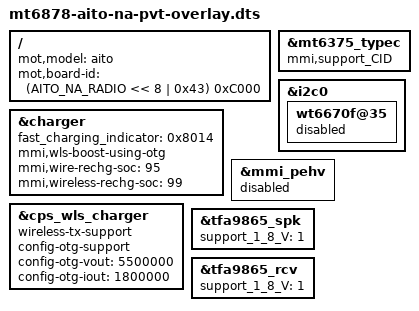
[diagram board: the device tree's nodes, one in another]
/* Copyright (c) 2023, Motorola Mobility Inc. All rights reserved.
 *
 * This program is free software; you can redistribute it and/or modify
 * it under the terms of the GNU General Public License version 2 and
 * only version 2 as published by the Free Software Foundation.
 *
 * This program is distributed in the hope that it will be useful,
 * but WITHOUT ANY WARRANTY; without even the implied warranty of
 * MERCHANTABILITY or FITNESS FOR A PARTICULAR PURPOSE.  See the
 * GNU General Public License for more details.
 */

/dts-v1/;
/plugin/;

#include "mediatek/mt6878-aito-common-overlay.dtsi"

#define AITO_NA_RADIO 1

/* Board match root node */
/ {
	fragment@model {
		target-path = "/";
		__overlay__ {
			mot,model = "aito";
			mot,board-id = <(AITO_NA_RADIO << 8 | 0x43) 0xC000>;
		};
	};
};

&mt6375_typec {
       mmi,support_CID;
};

&i2c0 {
	wt6670f@35 {
		status = "disabled";
	};
};

&charger {
	/*pe5 && pdc && wlc*/
	fast_charging_indicator = <0x8014>;
	mmi,wls-boost-using-otg;
	mmi,wire-rechg-soc = <95>;
	mmi,wireless-rechg-soc = <99>;
};

&mmi_pehv {
	status = "disabled";
};

&cps_wls_charger {
	wireless-tx-support;
	config-otg-support;
	config-otg-vout = <5500000>;
	config-otg-iout = <1800000>;
};

&tfa9865_spk {
    support_1_8_V=<1>;
};

&tfa9865_rcv {
    support_1_8_V=<1>;
};

#include <aito_pvt/cust.dtsi>
/*End of this file, DO NOT ADD ANYTHING HERE*/
